# TLE985x register map
Vendor: Infineon Technologies AG; File version: 1.3
CPU: CM0 r0p0, little endian, no MPU, no FPU, 2 interrupt priority bits
Registers are 32-bit, read-write, no defined reset value unless marked. A register's access mark holds for its fields unless they carry their own. Offsets are from the block's base; [hi:lo] are bit positions; {n}, {i} and the like mark numbered series; 'fields as' and 'values as' point back to an identical list.

## SCU
Base 0x50005000
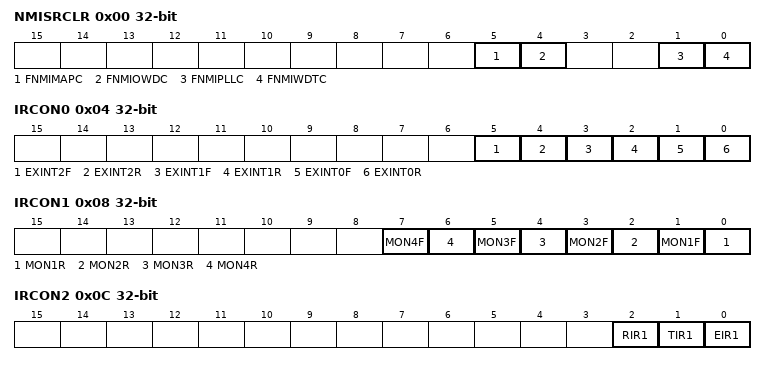
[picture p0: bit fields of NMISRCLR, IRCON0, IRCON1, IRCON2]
0x00 NMISRCLR wo — NMI Status Clear Register
  [all] fields
    0=Not Cleared (Interrupt event is not cleared.); 1=Cleared (Interrupt event is cleared)
  [5] FNMIMAPC — NVM Map Error NMI Flag
  [4] FNMIOWDC — Oscillator Watchdog NMI Flag
  [1] FNMIPLLC — PLL NMI Flag
  [0] FNMIWDTC — Watchdog Timer NMI Flag
0x04 IRCON0 ro — Interrupt Request Register 0
  [5] EXINT2F — Interrupt Flag for External Interrupt 2x on falling edge
    0=Int (Interrupt on falling edge event has not occurred.); 1=no Int (Interrupt on falling edge event has occurred.)
  [4] EXINT2R — Interrupt Flag for External Interrupt 2x on rising edge
    0=Int (Interrupt on rising edge event has not occurred.); 1=no Int (Interrupt on rising edge event has occurred.)
  [3] EXINT1F — Interrupt Flag for External Interrupt 1x on falling edge
    values as EXINT2F
  [2] EXINT1R — Interrupt Flag for External Interrupt 1x on rising edge
    values as EXINT2R
  [1] EXINT0F — Interrupt Flag for External Interrupt 0x on falling edge
    values as EXINT2F
  [0] EXINT0R — Interrupt Flag for External Interrupt 0x on rising edge
    values as EXINT2R
0x08 IRCON1 ro — Interrupt Request Register 1
  [2n-1] MON{n}F (n=1..4) — Interrupt Flag for MON{n}x on falling edge
    0=No Int (Interrupt on falling edge event has not occurred.); 1=Int (Interrupt on falling edge event has occurred.)
  [2n-2] MON{n}R (n=1..4) — Interrupt Flag for MON{n}x on rising edge
    0=No Int (Interrupt on rising edge event has not occurred.); 1=Int (Interrupt on rising edge event has occurred.)
0x0C IRCON2 ro — Interrupt Request Register 2
  [all] fields
    values as the fields of NMISRCLR
  [2] RIR1 — Receive Interrupt Flag for SSC1
  [1] TIR1 — Transmit Interrupt Flag for SSC1
  [0] EIR1 — Error Interrupt Flag for SSC1
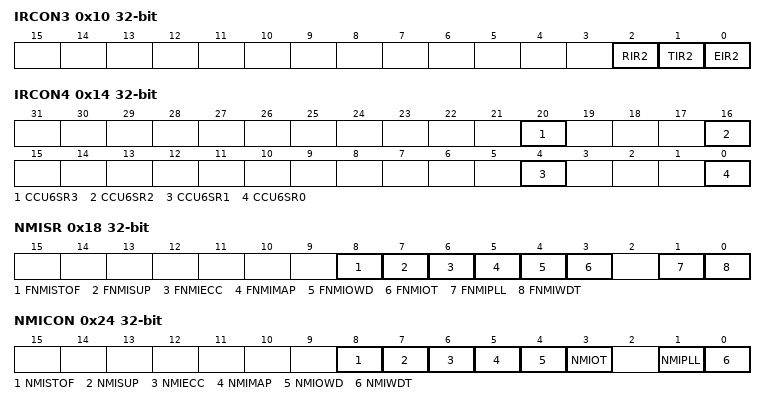
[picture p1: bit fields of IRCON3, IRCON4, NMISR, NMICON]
0x10 IRCON3 ro — Interrupt Request Register 3
  [all] fields
    values as the fields of NMISRCLR
  [2] RIR2 — Receive Interrupt Flag for SSC2
  [1] TIR2 — Transmit Interrupt Flag for SSC2
  [0] EIR2 — Error Interrupt Flag for SSC2
0x14 IRCON4 ro — Interrupt Request Register 4
  [all] fields
    values as the fields of NMISRCLR
  [20] CCU6SR3 — Interrupt Flag 1 for CCU6
  [16] CCU6SR2 — Interrupt Flag 1 for CCU6
  [4] CCU6SR1 — Interrupt Flag 1 for CCU6
  [0] CCU6SR0 — Interrupt Flag 1 for CCU6
0x18 NMISR ro — NMI Status Register
  [8] FNMISTOF — Stack Overflow NMI Flag
    0=no Int (No supply prewarning NMI has occurred.); 1=Int (Supply prewarning has occurred.)
  [7] FNMISUP — Supply Prewarning NMI Flag
    values as FNMISTOF
  [6] FNMIECC — ECC Error NMI Flag
    0=no Int (No uncorrectable ECC error has occurred on NVM, XRAM.); 1=Int (Uncorrectable ECC error has occurred on NVM, RAM.)
  [5] FNMIMAP — NVM Map Error NMI Flag
    0=no Int (No NVM Map Error NMI has occurred.); 1=Int (NVM Map Error has occurred.)
  [4] FNMIOWD — Oscillator Watchdog NMI Flag
    0=no Int (No oscillator watchdog NMI has occurred.); 1=Int (Oscillator watchdog event has occurred.)
  [3] FNMIOT — Overtemperature NMI Flag
    0=no Int (No OT NMI has occurred.); 1=Int (OT NMI event has occurred.)
  [1] FNMIPLL — PLL NMI Flag
    0=no Int (No PLL NMI has occurred.); 1=Int (PLL loss-of-lock to the external crystal has occurred.)
  [0] FNMIWDT — Watchdog Timer NMI Flag
    0=no Int (No watchdog NMI has occurred.); 1=Int (WDT prewarning has occurred.)
0x1C IEN0 — Interrupt Enable Register 0
  [31] EA — Global Interrupt Mask
    0=disable (All pending interrupt requests (except NMI) are blocked from the core.); 1=enable (Pending interrupt requests are not blocked from the core.)
0x20 VTOR — Vector Table Reallocation Register
  [1:0] VTOR_BYP — Vector Table Bypass Mode
    0=ROM (VTOR is not remapped (ROM)); 1=RAM (VTOR is remapped to RAM); 2=NVM_BSL (VTOR is remapped to NVM); 3=NVM_LIN (VTOR is remapped to NVM)
0x24 NMICON — NMI Control Register
  [8] NMISTOF — Stack Overflow NMI Enable
    0=disable (Stack overflow NMI is disabled.); 1=enable (Stack overflow NMI is enabled.)
  [7] NMISUP — Supply Prewarning NMI Enable
    0=disable (Supply NMI is disabled.); 1=enable (Supply NMI is enabled.)
  [6] NMIECC — ECC Error NMI Enable
    0=disable (ECC Error NMI is disabled.); 1=enable (ECC Error NMI is enabled.)
  [5] NMIMAP — NVM Map Error NMI Enable
    0=disable (NVM Map Error NMI is disabled.); 1=enable (NVM Map Error NMI is enabled.)
  [4] NMIOWD — Oscillator Watchdog NMI Enable
    0=disable (Oscillator watchdog NMI is disabled.); 1=enable (Oscillator watchdog NMI is enabled.)
  [3] NMIOT — NMI OT Enable
    0=disable (NMI OT is disabled.); 1=enable (NMI OT is enabled.)
  [1] NMIPLL — PLL Loss of Lock NMI Enable
    0=disable (PLL Loss of Lock NMI is disabled.); 1=enable (PLL Loss of Lock NMI is enabled.)
  [0] NMIWDT — Watchdog Timer NMI Enable
    0=disable (WDT NMI is disabled.); 1=enable (WDT NMI is enabled.)
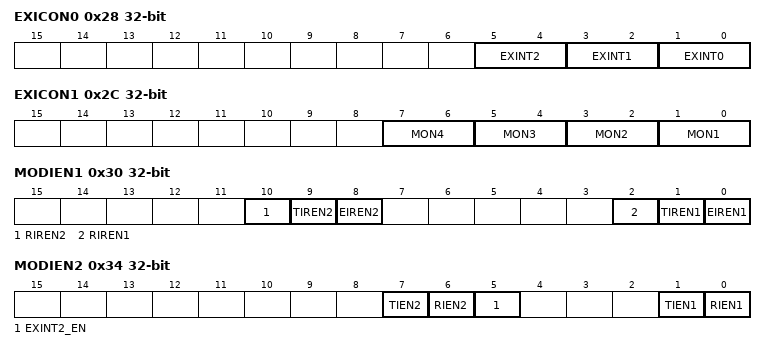
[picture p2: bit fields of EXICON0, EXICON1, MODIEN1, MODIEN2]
0x28 EXICON0 — External Interrupt Control Register 0
  [5:4] EXINT2 — External Interrupt 2 Trigger Select
    0=disable (Interrupt disabled.); 1=rising (Interrupt on rising edge.); 2=falling (Interrupt on falling edge.); 3=both (Interrupt on both rising and falling edge.)
  [3:2] EXINT1 — External Interrupt 1 Trigger Select
    values as EXINT2
  [1:0] EXINT0 — External Interrupt 0 Trigger Select
    0=enable (Interrupt disabled.); 1=rising (Interrupt on rising edge.); 2=falling (Interrupt on falling edge.); 3=both (Interrupt on both rising and falling edge.)
0x2C EXICON1 — External Interrupt Control Register 1
  [all] fields
    0=disable (external interrupt MON is disabled.); 1=rising (Interrupt on rising edge.); 2=falling (Interrupt on falling edge.); 3=both (Interrupt on both rising and falling edge.)
  [2n-1:2n-2] MON{n} (n=1..4) — MON{n} Input Trigger Select
0x30 MODIEN1 — Peripheral Interrupt Enable Register 1
  [10] RIREN2 — SSC 2 Receive Interrupt Enable
    0=Disable (Receive interrupt is disabled); 1=Enable (Receive interrupt is enabled)
  [9] TIREN2 — SSC 2 Transmit Interrupt Enable
    0=Disable (Transmit interrupt is disabled); 1=Enable (Transmit interrupt is enabled)
  [8] EIREN2 — SSC 2 Error Interrupt Enable
    0=Disable (Error interrupt is disabled); 1=Enable (Error interrupt is enabled)
  [2] RIREN1 — SSC 1 Receive Interrupt Enable
    values as RIREN2
  [1] TIREN1 — SSC 1 Transmit Interrupt Enable
    values as TIREN2
  [0] EIREN1 — SSC 1 Error Interrupt Enable
    values as EIREN2
0x34 MODIEN2 — Peripheral Interrupt Enable Register 2
  [7] TIEN2 — UART 2 Transmit Interrupt Enable
    values as MODIEN1.TIREN2
  [6] RIEN2 — UART 2 Receive Interrupt Enable
    values as MODIEN1.RIREN2
  [5] EXINT2_EN — External Interrupt 2 Enable
    0=Disable (External interrupt is disabled); 1=Enable (External interrupt is enabled)
  [1] TIEN1 — UART 1 Transmit Interrupt Enable
    values as MODIEN1.TIREN2
  [0] RIEN1 — UART 1 Receive Interrupt Enable
    values as MODIEN1.RIREN2
0x38 MODIEN3 — Peripheral Interrupt Enable Register 3
  [0] IE0 — External Interrupt Enable
    0=disabled; 1=enabled
0x3C MODIEN4 — Peripheral Interrupt Enable Register 4
  [0] IE1 — External Interrupt Enable
    0=disabled; 1=enabled
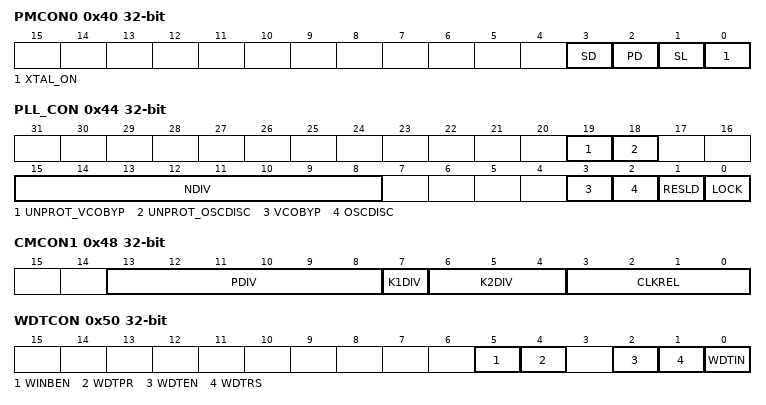
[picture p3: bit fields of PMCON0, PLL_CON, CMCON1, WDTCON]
0x40 PMCON0 — Power Mode Control Register 0
  [3] SD — Slow Down Mode Enable. Active High.
  [2] PD — Power Down Mode Enable. Active High.
  [1] SL — Sleep Mode Enable. Active High.
  [0] XTAL_ON — OSC_HP Operation in Power Down Mode
    0=PD (OSC_HP (XTAL) will be put to Power Down mode by hardware in power save mode.); 1=ON (OSC_HP (XTAL) continues to operate in Power Down mode, if enabled by SCU_OSC_CON.XPD.)
0x44 PLL_CON access per field — PLL Control Register
  [19] UNPROT_VCOBYP wo — Unprotect write access of VCO_BYP
  [18] UNPROT_OSCDISC wo — Unprotect write access of OSC_DISC
  [15:8] NDIV rw — PLL N-Divider
    0=N = 39, ; 38=N = 39; 39=N = 39, ; 80=N = 80 (default), ; 200=N = 200; 201=N = 200, ; 255=N = 200
  [3] VCOBYP rw — PLL VCO Bypass Mode Select
    0=Normal (or freerunning) operation (default); 1=Prescaler Mode; VCO is bypassed (PLL output clock is derived from input clock divided by K1-divider)
  [2] OSCDISC rw — Oscillator Disconnect
    0=Connect (Oscillator is connected to the PLL); 1=Disconnect (Oscillator is disconnected to the PLL.)
  [1] RESLD rw — Restart Lock Detection
    0=No reset (No effect.); 1=Reset lock flag and restart lock detection
  [0] LOCK ro — PLL Lock Status Flag
    0=Not Locked (The frequency difference of fREF and fDIV is greater than allowed. The VCO part of the PLL can not lock on a target frequency.); 1=Locked (The frequency difference of fREF and fDIV is small enough to enable a stable VCO operation.)
0x48 CMCON1 — Clock Control Register 1
  [13:8] PDIV — PLL PDIV-Divider:
    {v}=P = 4 (v=0..4); 5=P = 5 (default); 6=P = 6, ; 50=P = 50; 51=P = 50, ; 63=P = 50
  [7] K1DIV — PLL K1-Divider
    0=div 2 (K1 = 2); 1=div 1 (K1 = 1)
  [6:4] K2DIV — PLL K2-Divider
    0=div 2 (K2 = 2 (default)); {v}=div {v+2} (K2 = {v+2}) (v=1..7)
  [3:0] CLKREL — Slow Down Clock Divider for fCCLK Generation
    0=div 1 (fsys); 1=div 2 (fsys/2); 2=div 3 (fsys/3); 3=div 4 (fsys/4); 4=div 8 (fsys/8); 5=div 16 (fsys/16); 6=div 24 (fsys/24); 7=div 32 (fsys/32); 8=div 48 (fsys/48); 9=div 64 (fsys/64); 10=div 96 (fsys/96); 11=div 128 (fsys/128); 12=div 192 (fsys/192); 13=div 256 (fsys/256); 14=div 384 (fsys/384); 15=div 512 (fsys/512)
0x4C CMCON2 — Clock Control Register 2
  [0] PBA0CLKREL — PBA0 Clock Divider
    0=div 1 (divide by 1); 1=div 2 (divide by 2)
0x50 WDTCON access per field — Watchdog Timer Control Register
  [5] WINBEN rw — Watchdog Window-Boundary Enable
    0=Disable (Watchdog Window-Boundary feature is disabled. (default)); 1=Enable (Watchdog Window-Boundary feature is enabled.)
  [4] WDTPR ro — Watchdog Prewarning Mode Flag
    0=Normal mode (default after reset); 1=Prewarn (The Watchdog is operating in Prewarning Mode)
  [2] WDTEN rw — WDT Enable
    0=Disable (WDT is disabled); 1=Enable (WDT is enabled)
  [1] WDTRS rw — WDT Refresh Start
  [0] WDTIN rw — Watchdog Timer Input Frequency Selection
    0=DIV 2 (Input frequency is fPCLK/2); 1=DIV 128 (Input frequency is fPCLK/128)
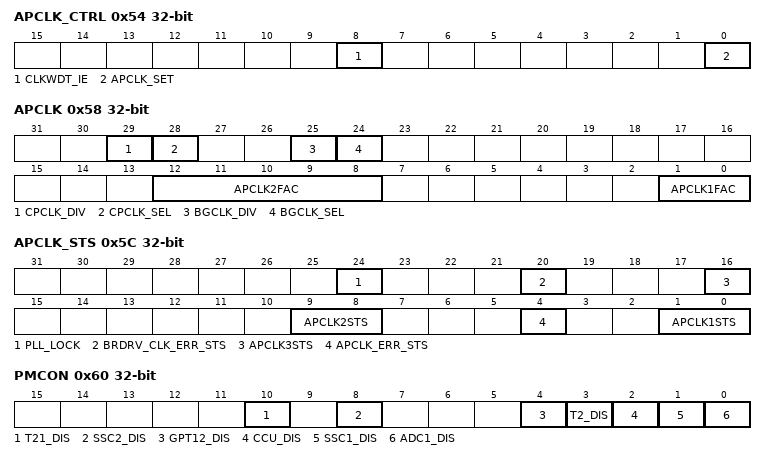
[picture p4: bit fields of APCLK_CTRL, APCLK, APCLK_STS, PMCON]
0x54 APCLK_CTRL — Analog Peripheral Clock Control Register
  [8] CLKWDT_IE — Clock Watchdog Interrupt Enable
    0=disabled (Interrupt disabled); 1=enabled (Interrupt enabled)
  [0] APCLK_SET — Set and Overtake Flag for Clock Settings
    0=ignore (Clock Settings are ignored (previous values are held)); 1=update (Clock Settings are overtaken)
0x58 APCLK — Analog Peripheral Clock Register
  [29] CPCLK_DIV — Charge Pump Clock Divider
    0=div 2 (divide by 2); 1=div 1 (divide by 1)
  [28] CPCLK_SEL — Charge Pump Clock Selection
    0=LP_CLK (LP_CLK is selected); 1=fsys is selected
  [25] BGCLK_DIV — Bandgap Clock Divider
    0=div 2 (divide by 2); 1=div 1 (divide by 1)
  [24] BGCLK_SEL — Bandgap Clock Selection
    0=LP_CLK (LP_CLK is selected); 1=fsys is selected
  [12:8] APCLK2FAC — Slow Down Clock Divider for TFILT_CLK Generation
    0=div 1 (fsys); {v}=div {v+1} (fsys/{v+1}) (v=1..11); 30=div 31 (fsys/31); 31=div 32 (fsys/32)
  [1:0] APCLK1FAC — Analog Module Clock Factor
    {v}=div {v+1} (Divide by {v+1}) (v=0..3)
0x5C APCLK_STS ro — Analog Peripheral Clock Status Register
  [24] PLL_LOCK — PLL LOCK Status
    0=no lock (PLL has not locked); 1=lock (PLL has locked)
  [20] BRDRV_CLK_ERR_STS — BRDRV CLK Error Status
    0=no Error writing was not blocked; 1=Error writing was blocked
  [16] APCLK3STS — Loss of Clock Status
    0=No loss of clock; 1=Loss of clock occurred
  [9:8] APCLK2STS — Analog Peripherals Clock Status
    0=OK (The TFILT_CLK clock is in the required range); 1=Too high (The TFILT_CLK clock exceeds the higher limit); 2=Too low (The TFILT_CLK clock exceeds the lower limit); 3=Out of Limit (The TFILT_CLK clock is not inside the specified limit.)
  [4] APCLK_ERR_STS — APCLK Error Status
    values as BRDRV_CLK_ERR_STS
  [1:0] APCLK1STS — Analog Peripherals Clock Status
    0=OK (The MI_CLK clock is in the required range); 1=too high (The MI_CLK clock exceeds the higher limit); 2=too low (The MI_CLK clock exceeds the lower limit); 3=out of limit (The MI_CLK clock is not inside the specified limit.)
0x60 PMCON — Peripheral Management Control Register
  [10] T21_DIS — T21 Disable Request. Active high.
    0=Enable (T21 is in normal operation. (default)); 1=Disable (Request to disable the T21.)
  [8] SSC2_DIS — SSC Disable Request. Active high.
    0=Enable (SSC is in normal operation. (default)); 1=Disable (Request to disable the SSC.)
  [4] GPT12_DIS — General Purpose Timer 12 Disable Request. Active high.
    0=Enable (GPT12 is in normal operation. (default)); 1=Disable (Request to disable the GPT12.)
  [3] T2_DIS — T2 Disable Request. Active high.
    0=Enable (T2 is in normal operation. (default)); 1=Disable (Request to disable the T2.)
  [2] CCU_DIS — CCU Disable Request. Active high.
    0=Enable (CCU is in normal operation. (default)); 1=Disabel (Request to disable the CCU.)
  [1] SSC1_DIS — SSC Disable Request. Active high.
    values as SSC2_DIS
  [0] ADC1_DIS — ADC1 Disable Request. Active high.
    0=Enable (ADC1 is in normal operation. (default)); 1=Disable (Request to disable the ADC.)
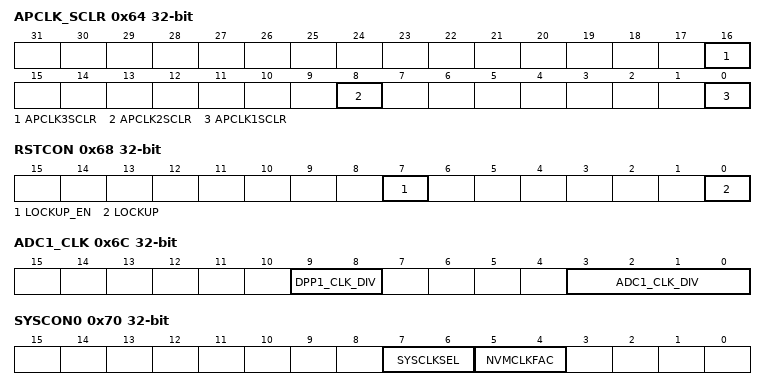
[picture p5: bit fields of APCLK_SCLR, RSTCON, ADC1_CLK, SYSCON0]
0x64 APCLK_SCLR wo — Analog Peripheral Clock Status Clear Register
  [16] APCLK3SCLR — Analog Peripherals Clock 3 Status Clear
  [8] APCLK2SCLR — Analog Peripherals Clock Status Clear
  [0] APCLK1SCLR — Analog Peripherals Clock Status Clear
0x68 RSTCON — Reset Control Register
  [7] LOCKUP_EN — Lockup Reset Enable Flag
    0=disable (Lockup is disabled.); 1=enable (Lockup is enabled.)
  [0] LOCKUP — Lockup Flag
    0=disable (Lockup Status not active.); 1=enable (Lockup Status active.)
0x6C ADC1_CLK — ADC1 Peripheral Clock Register
  [9:8] DPP1_CLK_DIV — ADC1 Post processing clock divider
    {v}=div {v+1} (Divide by {v+1}) (v=0..3)
  [3:0] ADC1_CLK_DIV — ADC1 Clock divider
    {v}=div {v+1} (Divide by {v+1}) (v=0..7); 14=div 15 (Divide by 15); 15=div 16 (Divide by 16)
0x70 SYSCON0 access per field — System Control Register 0
  [7:6] SYSCLKSEL rw — System Clock Select
    0=f_pll (The PLL clock output signal fPLL is used); 1=f_osc (The direct clock input from fOSC is used); 2=f_lpclk (The direct low-precision clock input from fLP_CLK is used.); 3=f_int (The direct input from internal oscillator fINTOSC is used)
  [5:4] NVMCLKFAC ro — NVM Access Clock Factor
    {v}=div {v+1} (Divide by {v+1}) (v=0..3)
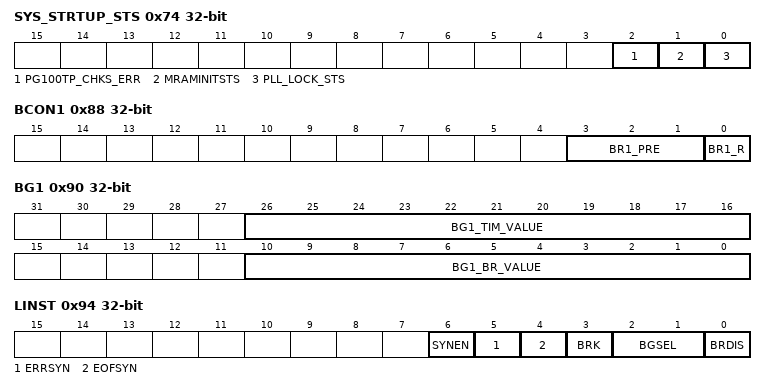
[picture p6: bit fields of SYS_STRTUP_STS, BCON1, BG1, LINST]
0x74 SYS_STRTUP_STS — System Startup Status Register
  [2] PG100TP_CHKS_ERR — 100 TP Page Checksum Error
    0=OK (initialisation of trimming parameters from NVM was successfull (checksum was correct)); 1=Not OK (initialisation of trimming parameter from NVM was not successfull (checksum was not correct). As a backup default values form Boot-ROM are used)
  [1] MRAMINITSTS — Map RAM Initialisation Status
    0=No Fail (Map RAM initialisation was successfull); 1=Fail (Map RAM initialisation was not successfull)
  [0] PLL_LOCK_STS — PLL LOCK STATUS
    0=No Fail; 1=Fail
0x78 WDTREL — Watchdog Timer Reload Register
  [7:0] WDTREL — Watchdog Timer Reload Value
0x7C WDTWINB — Watchdog Window-Boundary Count
  [7:0] WDTWINB — Watchdog Window-Boundary Count Value
0x80 WDT ro — Watchdog Timer
  [15:0] WDT — Watchdog Timer Current Value
0x88 BCON1 — Baud Rate Control Register 1
  [3:1] BR1_PRE — Prescaler Bit
    0=div 1 (fDIV = fPCLK); 1=div 2 (fDIV = fPCLK/2); 2=div 4 (fDIV = fPCLK/4); 3=div 8 (fDIV = fPCLK/8); 4=div 16 (fDIV = fPCLK/16); 5=div 32 (fDIV = fPCLK/32)
  [0] BR1_R — Baud Rate Generator Run Control Bit
    0=Disable (Baud-rate generator disabled.); 1=Enable (Baud-rate generator enabled.)
0x8C BGL1 — Baud Rate Timer/Reload Register, Low Byte 1
  [4:0] BG1_FD_SEL — Fractional Divider Selection
0x90 BG1 access per field — Baud Rate Timer/Reload Register
  [26:16] BG1_TIM_VALUE ro — Baud Rate Timer Value
    0=Bypassed (Baud-rate timer is bypassed.); 1=1; 2=2; 0x7FE=2046; 0x7FF=2047
  [10:0] BG1_BR_VALUE rw — Baud Rate Reload Value
    0=Bypass (Baud-rate timer is bypassed.); 1=1; 2=2; 0x7FE=2046; 0x7FF=2047
0x94 LINST access per field — LIN Status Register
  [6] SYNEN rw — End of SYN Byte and SYN Byte Error Interrupts Enable
    0=Disable (End of SYN Byte and SYN Byte Error Interrupts are not enabled.); 1=Enable (End of SYN Byte and SYN Byte Error Interrupts are enabled.)
  [5] ERRSYN ro — SYN Byte Error Interrupt Flag
    0=Disable (Error is not detected in SYN Byte.); 1=Enable (Error is detected in SYN Byte.)
  [4] EOFSYN ro — End of SYN Byte Interrupt Flag
    0=Disable (End of SYN Byte is not detected.); 1=Enable (End of SYN Byte is detected.)
  [3] BRK ro — Break Field Flag
    0=Disable (Break Field is not detected.); 1=Enable (Break Field is detected.)
  [2:1] BGSEL rw — Baud Rate Select for Detection
  [0] BRDIS rw — Baud Rate Detection Disable
    0=Disable (Break/Synch detection is enabled.); 1=Enable (Break/Synch detection is disabled.)
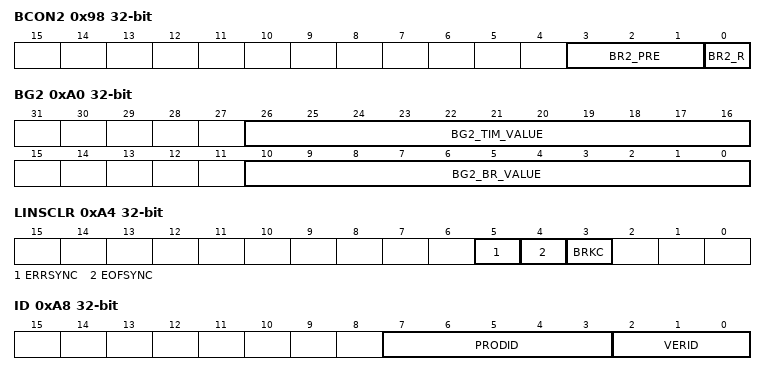
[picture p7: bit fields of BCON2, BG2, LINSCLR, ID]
0x98 BCON2 — Baud Rate Control Register 2
  [3:1] BR2_PRE — Prescaler Bit
    values as BCON1.BR1_PRE
  [0] BR2_R — Baud Rate Generator Run Control Bit
    values as BCON1.BR1_R
0x9C BGL2 — Baud Rate Timer/Reload Register, Low Byte 2
  [4:0] BG2_FD_SEL — Fractional Divider Selection
0xA0 BG2 access per field — Baud Rate Timer/Reload Register
  [26:16] BG2_TIM_VALUE ro — Baud Rate Timer Value
    values as BG1.BG1_TIM_VALUE
  [10:0] BG2_BR_VALUE rw — Baud Rate Reload Value
    values as BG1.BG1_BR_VALUE
0xA4 LINSCLR wo — LIN Status Clear Register
  [5] ERRSYNC — SYN Byte Error Interrupt Flag
    0=Not cleared (Error in SYN Byte not cleared.); 1=Cleared (Error in SYN Byte cleared.)
  [4] EOFSYNC — End of SYN Byte Interrupt Flag Clear
    0=Not cleared (End of SYN Byte is not cleared.); 1=Cleared (End of SYN Byte is cleared.)
  [3] BRKC — Break Field Flag Clear
    0=Not cleared (Break Field is not cleared.); 1=Cleared (Break Field is cleared.)
0xA8 ID ro — Identity Register
  [7:3] PRODID — Product ID
  [2:0] VERID — Version ID
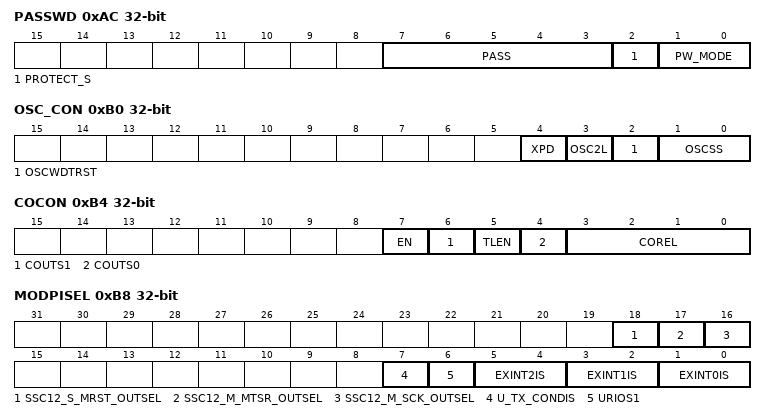
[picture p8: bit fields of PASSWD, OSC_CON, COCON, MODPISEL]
0xAC PASSWD access per field — Password Register
  [7:3] PASS rw — Password Bits
    24=Enables writing of the bit field MODE; 19=Opens access to writing of all protected bits; 21=Closes access to writing of all protected bits
  [2] PROTECT_S ro — Bit-Protection Signal Status Bit
    0=Not protected (Software is able to write to all protected bits.); 1=Protected (Software is unable to write to any protected bits.)
  [1:0] PW_MODE rw — Bit-Protection Scheme Control Bit
    0=Disable (Scheme Disabled); 3=Enable (Scheme Enabled (default))
0xB0 OSC_CON access per field — OSC Control Register
  [4] XPD rw — XTAL (OSC_HP) Power Down Control
    0=Enabled (XTAL (OSC_HP) is not powered down.); 1=Power down (XTAL (OSC_HP) is powered down.)
  [3] OSC2L ro — OSC-Too-Low Condition Flag
    0=OSC OK (fOSC is above threshold.); 1=OSC too low (fOSC is below threshold.)
  [2] OSCWDTRST rw — Oscillator Watchdog Reset
    0=No Reset (No effect.); 1=Reset OSC2L flag and restart the oscillator watchdog of the PLL
  [1:0] OSCSS rw — Oscillator Source Select
    0=f_int_sync (PLL internal oscillator OSC_PLL (fINT) is selected synchronously as fR.); 1=Xtal_sync (XTAL (fOSC from OSC_HP) is selected synchronously as fR.); 2=f_int_async (PLL internal oscillator OSC_PLL (fINT) is selected asynchronously as fR.)
0xB4 COCON — Clock Output Control Register
  [7] EN — CLKOUT Enable
    0=disable (No external clock signal is provided); 1=enable (The configured external clock signal is provided)
  [6] COUTS1 — Clock Out Source Select Bit 1
    0=fCCLK is selected; 1=COUTS0 (Based on setting of COUTS0.)
  [5] TLEN — Toggle Latch Enable
    0=disable (Toggle Latch is disabled. Clock output frequency is chosen by the bit field COREL.); 1=enable (Toggle Latch is enabled. Clock output frequency is half of the frequency that is chosen by the bit field COREL. The resulting output frequency has 50 percent duty cycle.)
  [4] COUTS0 — Clock Out Source Select Bit 0
    0=Osc (Oscillator output frequency is selected.); 1=COREL (Clock output frequency is chosen by the bit field COREL.)
  [3:0] COREL — Clock Output Divider
    0=div 1 (fsys); 1=div 2 (fsys/2); 2=div 3 (fsys/3); 3=div 4 (fsys/4); 4=div 6 (fsys/6); 5=div 8 (fsys/8); 6=div 10 (fsys/10); 7=div 12 (fsys/12); 8=div 14 (fsys/14); 9=div 16 (fsys/16); 10=div 18 (fsys/18); 11=div 20 (fsys/20); 12=div 24 (fsys/24); 13=div 32 (fsys/32); 14=div 36 (fsys/36); 15=div 40 (fsys/40)
0xB8 MODPISEL — Peripheral Input Select Register
  [18] SSC12_S_MRST_OUTSEL — Output selection for SSC12_S_MRST
    0=SSC1 (SSC1_S_MRST); 1=SSC2 (SSC2_S_MRST)
  [17] SSC12_M_MTSR_OUTSEL — Output selection for SSC12_M_MTSR
    0=SSC1 (SSC1_M_MTSR); 1=SSC2 (SSC2_M_MTSR)
  [16] SSC12_M_SCK_OUTSEL — Output selection for SSC12_M_SCK
    0=SSC1 (SSC1_M_SCK); 1=SSC2 (SSC2_M_SCK)
  [7] U_TX_CONDIS — UART1 TxD Connection Disable
    0=Enable (UART1-TX-Output -LIN Transmitter TX Input Connection available.); 1=Disable (UART1-TX-Output -LIN Transmitter TX Input Connection not available (can be stimulated by external port pin).)
  [6] URIOS1 — UART1 Input/Output Select
    0=Enable (UART1 Receiver Input RXD1_0 (Connection to LIN is available).); 1=Disable (UART1 Receiver Input RXD1_1 (Connection to LIN is not available).)
  [5:4] EXINT2IS — External Interrupt 2 Input Select
    {v}=EXINT2_{v} (External Interrupt Input EXINT2_{v} is selected.) (v=0..3)
  [3:2] EXINT1IS — External Interrupt 1 Input Select
    {v}=EXINT1_{v} (External Interrupt Input EXINT1_{v} is selected.) (v=0..3)
  [1:0] EXINT0IS — External Interrupt 0 Input Select
    {v}=EXINT0_{v} (External Interrupt Input EXINT0_{v} is selected.) (v=0..3)
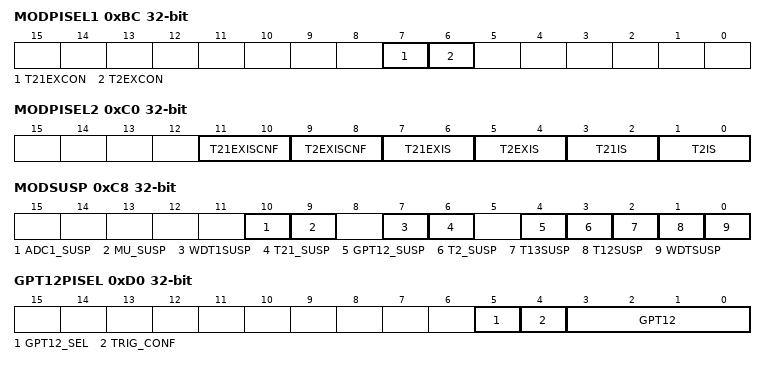
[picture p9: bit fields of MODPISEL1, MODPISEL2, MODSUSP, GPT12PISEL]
0xBC MODPISEL1 — Peripheral Input Select Register 1
  [7] T21EXCON — Timer 21 External Input Control
    0=MODPISEL (Timer 21 Input T21EX is selected by bit field SCU_MODPISEL2.T21EXIS.); 1=CCU6 (Timer 21 Input T21EX is connected to signal from CCU6 (Output >cc6_ch0).)
  [6] T2EXCON — Timer 2 External Input Control
    0=MODPISEL (Timer 2 Input T2EX is selected by bit field SCU_MODPISEL2.T2EXIS.); 1=CCU (Timer 2 Input T2EX is connected to signal from CCU6 (Output >cc6_cout60).)
0xC0 MODPISEL2 — Peripheral Input Select Register 2
  [11:10] T21EXISCNF — Timer 21 External Input Select Configuration
    0=T21EX_x (Timer 21 Input T21EX_x is selected.); 1=MONx Input is selected; 2=T21EX_y (Timer 21 Input T21EX_x is selected..); 3=MONy (MONx Input is selected.)
  [9:8] T2EXISCNF — Timer 2 External Input Select Configuration
    0=T2EX_x (Timer 2 Input T2EX_x is selected.); 1=MONx Input is selected; 2=T2EX_y (Timer 2 Input T2EX_x is selected.); 3=MONy (MONx Input is selected.)
  [7:6] T21EXIS — Timer 21 External Input Select
    {v}=Timer 21 Input T21EX_{v} or MON{v+1} is selected (v=0..3)
  [5:4] T2EXIS — Timer 2 External Input Select
    {v}=Timer 2 Input T2EX_{v} or MON{v+1} is selected (v=0..3)
  [3:2] T21IS — Timer 21 Input Select
    0=T21_0 (Timer 21 Input T21_0 is selected.); 1=T21_1 (Timer 21 Input T21_1 is selected.); 2=T21_2 (Timer 21 Input T21_2 is selected.)
  [1:0] T2IS — Timer 2 Input Select
    0=T2_0 (Timer 2 Input T2_0 is selected.); 1=T2_1 (Timer 2 Input T2_1 is selected.); 2=T2_2 (Timer 2 Input T2_2 is selected.)
0xC4 MODPISEL3 — Peripheral Input Select Register 3
  [6] URIOS2 — UART2 Input/Output Select
    0=RXTX_0 (UART2 Receiver Input RXD2_0 and Transmitter Output TXD2_0 is selected.); 1=RXTX_1 (UART2 Receiver Input RXD2_1 and Transmitter Output TXD2_1 is selected.)
0xC8 MODSUSP — Module Suspend Control Register
  [10] ADC1_SUSP — ADC1 Unit Debug Suspend Bit
    0=No suspend (ADC1 will not be suspended.); 1=Suspend (ADC1 will be suspended.)
  [9] MU_SUSP — Measurement Unit Debug Suspend Bit
    0=No Suspend (MU will not be suspended.); 1=Suspend (MU will be suspended.)
  [7] WDT1SUSP — Watchdog Timer 1 Debug Suspend Bit
    0=No Suspend (WDT1 will not be suspended.); 1=Suspend (WDT1 will be suspended.)
  [6] T21_SUSP — Timer21 Debug Suspend Bit
    0=No Suspend (Timer21 will not be suspended.); 1=Suspend (Timer21 will be suspended.)
  [4] GPT12_SUSP — GPT12 Debug Suspend Bit
    0=No Suspend (GPT12 will not be suspended.); 1=Suspend (GPT12 will be suspended.)
  [3] T2_SUSP — Timer2 Debug Suspend Bit
    0=No Suspend (Timer2 will not be suspended.); 1=Suspend (Timer2 will be suspended.)
  [2] T13SUSP — Timer 13 Debug Suspend Bit
    0=No Suspend (Timer 13 in Capture/Compare Unit will not be suspended.); 1=Suspend (Timer 13 in Capture/Compare Unit will be suspended.)
  [1] T12SUSP — Timer 12 Debug Suspend Bit
    0=No Suspend (Timer 12 in Capture/Compare Unit will not be suspended.); 1=Suspend (Timer 12 in Capture/Compare Unit will be suspended.)
  [0] WDTSUSP — SCU Watchdog Timer Debug Suspend Bit
    0=No Suspend (WDT will not be suspended.); 1=Suspend (WDT will be suspended.)
0xD0 GPT12PISEL — GPT12 Peripheral Input Select Register
  [5] GPT12_SEL — CCU6 Trigger Configuration.
    0=T_21 (CCU6_INT is triggered by Timer21); 1=GPT12 (CCU6_INT is triggered by GPT12PISEL.GPT12)
  [4] TRIG_CONF — CCU6 Trigger Configuration.
    0=Single (Trigger is just for one measurement (default)); 1=Edge (Trigger is present until next input edge (selected by GPT12) - continuous measurement.)
  [3:0] GPT12 — GPT12 TIN3B / TIN4D Input Select
    0=CC60; 1=CC61; 2=CC62; 3=T12 ZM; 4=T12 PM; 5=T12 CM0; 6=T12 CM1; 7=T12 CM2; 8=T13 PM; 9=T13 ZM; 10=T13 CM; 11=Edge (any pos or neg edge on CC60/61/62)
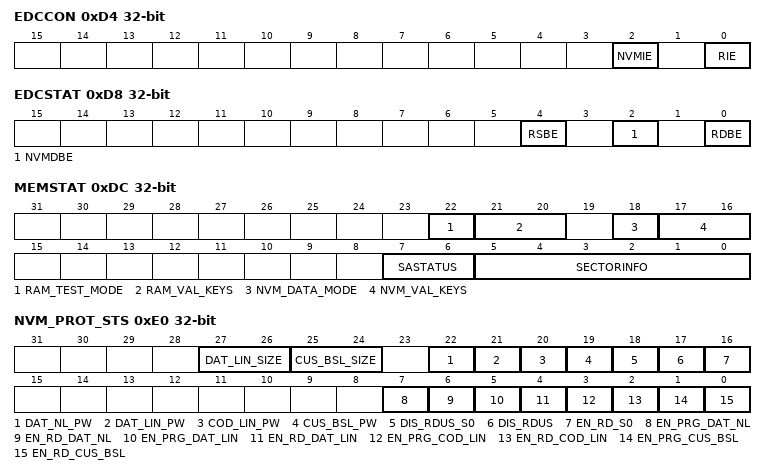
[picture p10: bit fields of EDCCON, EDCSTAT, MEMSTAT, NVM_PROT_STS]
0xD4 EDCCON — Error Detection and Correction Control Register
  [2] NVMIE — NVM Double Bit ECC Error Interrupt Enable
    0=Disable (No NMI is generated when a double bit ECC error occurs reading NVM.); 1=Enable (An NMI is generated when a double bit ECC error occurs reading NVM.)
  [0] RIE — RAM Double Bit ECC Error Interrupt Enable
    0=Disable (No NMI is generated when a double bit ECC error occurs reading RAM.); 1=Enable (An NMI is generated when a double bit ECC error occurs reading RAM.)
0xD8 EDCSTAT ro — Error Detection and Correction Status Register
  [4] RSBE — RAM Single Bit Error
    0=No Error (No single bit error on RAM has occurred.); 1=Error (A single bit error on RAM has occurred.)
  [2] NVMDBE — NVM Double Bit Error
    0=No Error (No double bit error on NVM has occurred.); 1=Error (A double bit error on NVM has occurred.)
  [0] RDBE — RAM Double Bit Error
    0=No Error (No double bit error on RAM has occurred.); 1=Error (A double bit error on RAM has occurred.)
0xDC MEMSTAT — Memory Status Register
  [22] RAM_TEST_MODE — RAM Data Mode
    0=Full (RAM test at cold reset executed on the whole RAM); 1=1K (RAM test at cold reset executed only on 1st kb of RAM)
  [21:20] RAM_VAL_KEYS — RAM valid keys
  [18] NVM_DATA_MODE
    0=1 Non linearly mapped data sector; 1=2 linearly mapped data sectors
  [17:16] NVM_VAL_KEYS — NVM valid keys
  [7:6] SASTATUS — Service Algorithm Status
    0=Success_1 (Depending on SECTORINFO, there are two possible outcomes: For SECTORINFO = 00H, NVM initialization is successful and no SA is executed. For SECTORINFO = values other than 00H, SA execution is successful and only one map error is fixed.); 1=Success_2 (SA execution is successful. More than one mapping error is fixed.); 2=Error_1 (SA execution is not successful. Map error exists); 3=Error_2 (NVM initialization failed, SA called but no page to be repaired has been found. Soft error present.)
  [5:0] SECTORINFO — Sector Information
0xE0 NVM_PROT_STS ro — NVM Protection Status Register
  [27:26] DAT_LIN_SIZE — Data linear Region Size Definition
    0=0K (data linear Size is 0K); 1=4K (data linear Size is 4K); 2=8K (data linear Size is 8K); 3=12K (data linear Size is 12K)
  [25:24] CUS_BSL_SIZE — CBSL Region Size Definition
    0=0K (CBSL Size is 0K); 1=4K (CBSL Size is 4K); 2=8K (CBSL Size is 8K); 3=16K (CBSL Size is 16K)
  [22] DAT_NL_PW — Status of Non-Linear Region Password / Protection
    0=Not Protected (Non-Linear Region Password is not installed; Linear region is not protected.); 1=Protected (Non-Linear Region Password is installed; Linear region is protected.)
  [21] DAT_LIN_PW — Status of Data linear Region Password / Protection
    0=Not protected (Non-Linear Region Password is not installed; Linear region is not protected.); 1=Protected (Non-Linear Region Password is installed; Linear region is protected.)
  [20] COD_LIN_PW — Status of Linear Region Password / Protection
    0=Not Protected (Linear Region Password is not installed; Linear region is not protected.); 1=Protected (Linear Region Password is installed; Linear region is protected.)
  [19] CUS_BSL_PW — Status of CBSL Region Password / Protection
    0=Not Protected (CBSL Region Password is not installed; CBSL region is not protected.); 1=Protected (CBSL Region Password is installed; CBSL region is protected.)
  [18] DIS_RDUS_S0 — Configuration of NVM Read Protection for Sector 0 with EN_RD_S0 = 0
    0=Not Protected (only active when nvm_read_S0_unsafe_i = 1 and not for nvm_read_S0_unsafe_i = 0); 1=Protected (independent from nvm_read_S0_unsafe_i; Also write accesess to Sector 0 are prevented)
  [17] DIS_RDUS — Configuration of NVM Read Protection for Sector 1...n with EN_RD_* = 0
    0=Not Protected (only active when nvm_read_unsafe_i = 1 and not for nvm_read_unsafe_i = 0); 1=Protected (independent from nvm_read_unsafe_i; Also write accesess to Sector 1...n are prevented)
  [16] EN_RD_S0 — NVM Read Protection for Sector 0
    0=Protected (The data in sector 0 can not be read over AHB-Lite Interface); 1=Not Protected (The data in sector 0 can be read over AHB-Lite Interface)
  [7] EN_PRG_DAT_NL — NVM Protection of Data in Non-Linear Data Sectors
    0=Protected (The data in sectors of the non-linearly mapped area can not be changed); 1=Not Protected (The data in sectors of the non-linearly mapped area can be changed (erased or written))
  [6] EN_RD_DAT_NL — NVM Read Protection of Data in Non-Linear Data Sectors
    0=Protected (The data in sectors of the non-linearly mapped area can not be read); 1=Not Protected (The data in sectors of the non-linearly mapped area can be read)
  [5] EN_PRG_DAT_LIN — NVM Protection of Data in Linear Data Sectors
    0=Protected (The data in sectors of the linearly mapped area can not be changed); 1=Not Protected (The data in sectors of the linearly mapped area can be changed (erased or written))
  [4] EN_RD_DAT_LIN — NVM Read Protection of Data in Linear Data Sectors
    0=Protected (The data in sectors of the linearly mapped area can not be read); 1=Not Protected (The data in sectors of the linearly mapped area can be read)
  [3] EN_PRG_COD_LIN — NVM Protection of Data in Linear Code Sectors
    values as EN_PRG_DAT_LIN
  [2] EN_RD_COD_LIN — NVM Read Protection of Data in Linear Code Sectors
    values as EN_RD_DAT_LIN
  [1] EN_PRG_CUS_BSL — NVM Protection of Data in Customer BSL Region
    0=Protected (The data in region defined by NVMBSL can not be changed); 1=Not Protected (The data in region defined by NVMBSL can be changed (erased or written))
  [0] EN_RD_CUS_BSL — NVM Read Protection of Data in Customer BSL Region
    0=Protected (The data in region defined by NVMBSL can not be read); 1=Not Protected (The data in region defined by NVMBSL sectors of can be read)
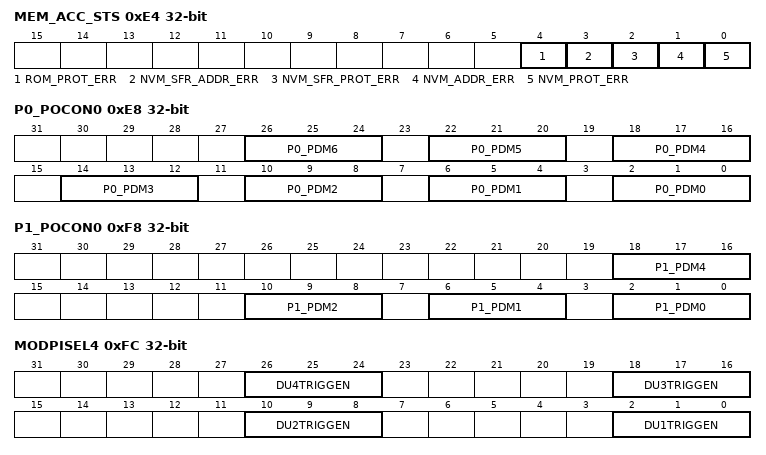
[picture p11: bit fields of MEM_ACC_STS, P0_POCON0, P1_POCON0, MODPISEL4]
0xE4 MEM_ACC_STS ro — Memory Access Status Register
  [all] fields
    0=No Error (No Protection error); 1=Error (Protection error)
  [4] ROM_PROT_ERR — ROM Access Protection
  [3] NVM_SFR_ADDR_ERR — NVM SFR Address Protection
  [2] NVM_SFR_PROT_ERR — NVM SFR Access Protection
  [1] NVM_ADDR_ERR — NVM Address Protection
  [0] NVM_PROT_ERR — NVM Access Protection
0xE8 P0_POCON0 — Port Output Control Register
  [all] fields
    0=Strong-sharp (Strong driver and sharp edge mode); 1=Strong-med (Strong driver and medium edge mode); 2=Strong-soft (Strong driver and soft edge mode); 3=Weak driver; 4=Medium driver
  [26:24] P0_PDM6 — P0.6 Port Driver Mode
  [22:20] P0_PDM5 — P0.5 Port Driver Mode
  [18:16] P0_PDM4 — P0.4 Port Driver Mode
  [14:12] P0_PDM3 — P0.3 Port Driver Mode
  [10:8] P0_PDM2 — P0.2 Port Driver Mode
  [6:4] P0_PDM1 — P0.1 Port Driver Mode
  [2:0] P0_PDM0 — P0.0 Port Driver Mode
0xEC WAKECON — Wakeup Interrupt Control Register
  [0] WAKEUPEN — Wakeup Interrupt Enable
    0=disable (wakeup interrupt is disabled.); 1=enable (wakeup interrupt is enabled.)
0xF0 IRCON5 ro — Interrupt Request Register 5
  [0] WAKEUP — Interrupt Flag for Wakeup
    values as the fields of NMISRCLR
0xF4 TCCR — Temperature Compensation Control Register
  [1:0] TCC — Temperature Compensation Control
    0=T1 (TJ: -40 degree C to 0 degree C); 1=T2 (TJ: 0 degree C to 40 degree C); 2=T3 (TJ: 40 degree C to 80 degree C); 3=T4 (TJ: 80 degree C to 150 degree C)
0xF8 P1_POCON0 — Port Output Control Register
  [18:16] P1_PDM4 — P1.4 Port Driver Mode
    values as the fields of P0_POCON0
  [10:8] P1_PDM2 — P1.2 Port Driver Mode
    3=Weak driver; 4=Medium driver
  [6:4] P1_PDM1 — P1.1 Port Driver Mode
    3=Weak driver; 4=Medium driver
  [2:0] P1_PDM0 — P1.0 Port Driver Mode
    3=Weak driver; 4=Medium driver
0xFC MODPISEL4 — Peripheral Input Select Register 4
  [all] fields
    0=CC60 (CC60 is selected.); 1=CC61 (CC61 is selected.); 2=CC62 (CC62 is selected.); 3=COUT60 (COUT60 is selected.); 4=COUT61 (COUT61 is selected.); 5=COUT62 (COUT62 is selected.); 6=T3OUT (T3OUT is selected.); 7=COUT63 (COUT63 is selected.)
  [8n-6:8n-8] DU{n}TRIGGEN (n=1..4) — Differential Unit Trigger Enable
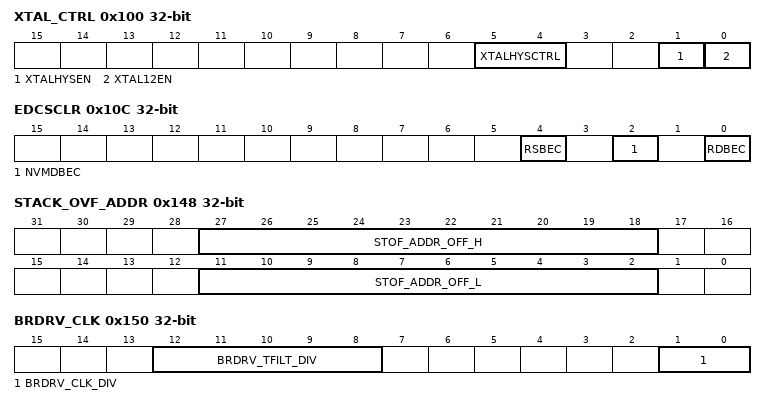
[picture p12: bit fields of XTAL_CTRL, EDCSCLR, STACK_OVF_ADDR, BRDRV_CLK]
0x100 XTAL_CTRL — Peripheral Input Select Register
  [5:4] XTALHYSCTRL — XTAL Hysteresis Control
    0=XHYST_0 (400mV nom.); 1=XHYST_1 (300mV nom.); 2=XHYST_2 (200mV nom.); 3=XHYST_3 (100mV nom.)
  [1] XTALHYSEN — XTAL Hysteresis Enable
    0=Disable (Hysteresis is disabled); 1=Enable (Hysteresis is enabled)
  [0] XTAL12EN — Pins XTAL1/2 Enable Bit
    0=Disable (Pins XTAL1/2 is not available. This setting overrides the .XPD setting.); 1=Enable (Pins XTAL1/2 are available)
0x10C EDCSCLR wo — Error Detection and Correction Status Clear Register
  [4] RSBEC — RAM Single Bit Error Clear
    0=Not cleared (A single bit error on RAM is not cleared.); 1=Cleared (A single bit error on RAM is cleared.)
  [2] NVMDBEC — NVM Double Bit Error Clear
    0=Not Cleared (A double bit error on NVM is not cleared.); 1=Cleared (A double bit error on NVM is cleared.)
  [0] RDBEC — RAM Double Bit Error Clear
    0=Not Cleared (A double bit error on RAM is not cleared.); 1=Cleared (A double bit error on RAM is cleared.)
0x12C STACK_OVFCLR wo — Stack Overflow Status Clear Register
  [0] STOF_STSC — Clear Stack Overflow Status
    0=Not Cleared (stack overflow not cleared.); 1=Cleared (stack overflow cleared.)
0x144 STACK_OVF_CTRL — Stack Overflow Control Register
  [0] STOF_EN — Stack Overflow Enable
    0=Disable (stack overflow detection disabled.); 1=Enable (stack overflow detection enabled)
0x148 STACK_OVF_ADDR — Stack Overflow Control Register
  [27:18] STOF_ADDR_OFF_H — Stack Overflow High Address Offset
  [11:2] STOF_ADDR_OFF_L — Stack Overflow Low Address Offset
0x14C STACK_OVF_STS — Stack Overflow Status Register
  [0] STOF_STS — Stack Overflow Status
    0=No Error (No stack overflow detected.); 1=Error (stack overflow detected.)
0x150 BRDRV_CLK — ADC1 Peripheral Clock Register
  [12:8] BRDRV_TFILT_DIV — Slow Down Clock Divider for TFILT_CLK Generation
    values as APCLK.APCLK2FAC
  [1:0] BRDRV_CLK_DIV — Analog Module Clock Factorf
    {v}=div {v+1} (Divide by {v+1}) (v=0..3)
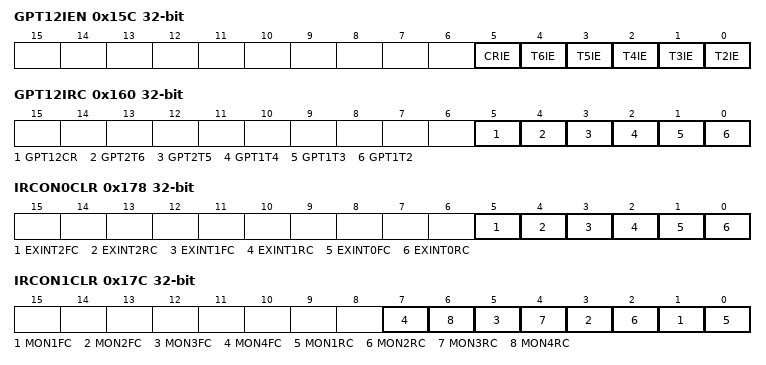
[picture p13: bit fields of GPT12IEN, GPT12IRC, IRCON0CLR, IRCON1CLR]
0x15C GPT12IEN — General Purpose Timer 12 Interrupt Enable Register
  [all] fields
    0=disabled; 1=enabled
  [5] CRIE — General Purpose Timer 12 Capture and Reload Interrupt Enable
  [n-2] T{n}IE (n=2..6) — General Purpose Timer 12 T{n} Interrupt Enable
0x160 GPT12IRC ro — Timer and Counter Control/Status Register
  [5] GPT12CR — GPT Module 1 Capture Reload Interrupt Status
    0=No Int (No Capture Reload Interrupt has occurred.); 1=Int (Capture Reload Interrupt has occurred.)
  [4] GPT2T6 — GPT Module 2Timer6 Interrupt Status
    0=No Int (No Timer 6 Interrupt has occurred.); 1=Int (Timer 6 Interrupt has occurred.)
  [3] GPT2T5 — GPT Module 2 Timer5 Interrupt Status
    0=No Int (No Timer 5 Interrupt has occurred.); 1=Int (Timer 5 Interrupt has occurred.)
  [2] GPT1T4 — GPT Module 1 Timer4 Interrupt Status
    0=No Int (No Timer 4 Interrupt has occurred.); 1=Int (Timer 4 Interrupt has occurred.)
  [1] GPT1T3 — GPT Module 1 Timer3 Interrupt Status
    0=No Int (No Timer 3 Interrupt has occurred.); 1=Int (Timer 3 Interrupt has occurred.)
  [0] GPT1T2 — GPT Module 1 Timer 2 Interrupt Status
    0=No Int (No Timer 2 Interrupt has occurred.); 1=Int (Timer 2 Interrupt has occurred.)
0x178 IRCON0CLR wo — Interrupt Request 0 Clear Register
  [all] fields
    0=not cleared (Interrupt event is not cleared.); 1=cleared (Interrupt event is cleared)
  [5] EXINT2FC — Interrupt Flag for External Interrupt 2x on falling edge
  [4] EXINT2RC — Interrupt Flag for External Interrupt 2x on rising edge
  [3] EXINT1FC — Interrupt Flag for External Interrupt 1x on falling edge
  [2] EXINT1RC — Interrupt Flag for External Interrupt 1x on rising edge
  [1] EXINT0FC — Interrupt Flag for External Interrupt 0x on falling edge
  [0] EXINT0RC — Interrupt Flag for External Interrupt 0x on rising edge
0x17C IRCON1CLR wo — Interrupt Request 1 Clear Register
  [all] fields
    values as the fields of NMISRCLR
  [2n-1] MON{n}FC (n=1..4) — Interrupt Flag for MON{n}x on falling edge
  [2n-2] MON{n}RC (n=1..4) — Interrupt Flag for MON{n}x on rising edge
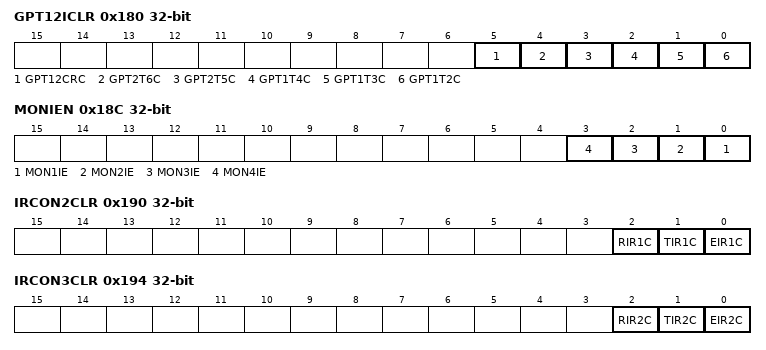
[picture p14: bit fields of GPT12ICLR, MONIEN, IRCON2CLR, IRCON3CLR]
0x180 GPT12ICLR wo — Timer and Counter Control/Status Clear Register
  [all] fields
    values as the fields of NMISRCLR
  [5] GPT12CRC — GPT Module 1 Capture Reload Interrupt Status
  [4] GPT2T6C — GPT Module 2Timer6 Interrupt Status
  [3] GPT2T5C — GPT Module 2 Timer5 Interrupt Status
  [2] GPT1T4C — GPT Module 1 Timer4 Interrupt Status
  [1] GPT1T3C — GPT Module 1 Timer3 Interrupt Status
  [0] GPT1T2C — GPT Module 1 Timer 2 Interrupt Status
0x18C MONIEN — Monitoring Input Interrupt Enable Register
  [all] fields
    0=disabled; 1=enabled
  [n-1] MON{n}IE (n=1..4) — MON {n} Interrupt Enable
0x190 IRCON2CLR wo — Interrupt Request 2 Clear Register
  [all] fields
    values as the fields of NMISRCLR
  [2] RIR1C — Receive Interrupt Flag for SSC1
  [1] TIR1C — Transmit Interrupt Flag for SSC1
  [0] EIR1C — Error Interrupt Flag for SSC1
0x194 IRCON3CLR wo — Interrupt Request 3 Clear Register
  [all] fields
    values as the fields of NMISRCLR
  [2] RIR2C — Receive Interrupt Flag for SSC2
  [1] TIR2C — Transmit Interrupt Flag for SSC2
  [0] EIR2C — Error Interrupt Flag for SSC2
0x198 IRCON4CLR wo — Interrupt Request 4 Clear Register
  [all] fields
    values as the fields of NMISRCLR
  [20] CCU6SR3C — Interrupt Flag 1 for CCU6
  [16] CCU6SR2C — Interrupt Flag 1 for CCU6
  [4] CCU6SR1C — Interrupt Flag 1 for CCU6
  [0] CCU6SR0C — Interrupt Flag 1 for CCU6
0x19C IRCON5CLR wo — Interrupt Request 5 Clear Register
  [0] WAKEUPC — Clear Flag for Wakeup Interrupt
    values as the fields of NMISRCLR
